# ATxmega128D3 device description
Architecture: AVR8_XMEGA; Family: AVR XMEGA
Registers are 8-bit, access not given, no defined reset value unless marked. A register's access mark holds for its fields unless they carry their own. Offsets are from the block's base; [hi:lo] are bit positions; {n}, {i} and the like mark numbered series; 'fields as' and 'values as' point back to an identical list.

## HIRES (TC module) — High-Resolution Extension
Instances: HIRESC 0x890
0x00 CTRLA — Control Register
  [1:0] HREN — High Resolution Enable
    0=NONE (No Fault Protection); 1=TC0 (Enable High Resolution on Timer/Counter 0); 2=TC1 (Enable High Resolution on Timer/Counter 1); 3=BOTH (Enable High Resolution both Timer/Counters)

## TC2 — 16-bit Timer/Counter type 2
Instances: TCC2 0x800, TCD2 0x900, TCE2 0xA00, TCF2 0xB00
0x00 CTRLA — Control Register A
  [3:0] CLKSEL — Clock Selection
    0=OFF (Timer Off); 1=DIV1 (System Clock); 2=DIV2 (System Clock / 2); 3=DIV4 (System Clock / 4); 4=DIV8 (System Clock / 8); 5=DIV64 (System Clock / 64); 6=DIV256 (System Clock / 256); 7=DIV1024 (System Clock / 1024); {v}=EVCH{v-8} (Event Channel {v-8}) (v=8..11)
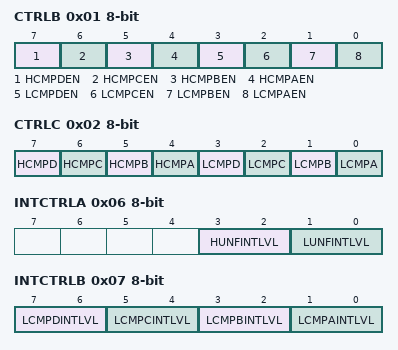
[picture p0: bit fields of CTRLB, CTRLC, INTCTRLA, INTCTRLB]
0x01 CTRLB — Control Register B
  [7] HCMPDEN — High Byte Compare D Enable
  [6] HCMPCEN — High Byte Compare C Enable
  [5] HCMPBEN — High Byte Compare B Enable
  [4] HCMPAEN — High Byte Compare A Enable
  [3] LCMPDEN — Low Byte Compare D Enable
  [2] LCMPCEN — Low Byte Compare C Enable
  [1] LCMPBEN — Low Byte Compare B Enable
  [0] LCMPAEN — Low Byte Compare A Enable
0x02 CTRLC — Control register C
  [7] HCMPD — High Byte Compare D Output Value
  [6] HCMPC — High Byte Compare C Output Value
  [5] HCMPB — High Byte Compare B Output Value
  [4] HCMPA — High Byte Compare A Output Value
  [3] LCMPD — Low Byte Compare D Output Value
  [2] LCMPC — Low Byte Compare C Output Value
  [1] LCMPB — Low Byte Compare B Output Value
  [0] LCMPA — Low Byte Compare A Output Value
0x04 CTRLE — Control Register E
  [1:0] BYTEM — Byte Mode
    0=NORMAL (16-bit mode); 1=BYTEMODE (Timer/Counter operating in byte mode only (TC2)); 2=SPLITMODE (Timer/Counter split into two 8-bit Counters)
0x06 INTCTRLA — Interrupt Control Register A
  [3:2] HUNFINTLVL — High Byte Underflow Interrupt Level
    0=OFF (Interrupt Disabled); 1=LO (Low Level); 2=MED (Medium Level); 3=HI (High Level)
  [1:0] LUNFINTLVL — Low Byte Underflow interrupt level
    values as HUNFINTLVL
0x07 INTCTRLB — Interrupt Control Register B
  [all] fields
    values as INTCTRLA.HUNFINTLVL
  [7:6] LCMPDINTLVL — Low Byte Compare D Interrupt Level
  [5:4] LCMPCINTLVL — Low Byte Compare C Interrupt Level
  [3:2] LCMPBINTLVL — Low Byte Compare B Interrupt Level
  [1:0] LCMPAINTLVL — Low Byte Compare A Interrupt Level
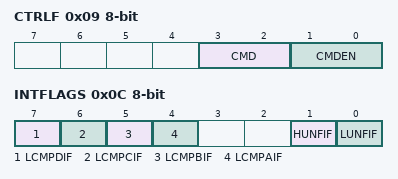
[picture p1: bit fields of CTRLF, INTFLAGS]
0x09 CTRLF — Control Register F
  [3:2] CMD — Command
    0=NONE (No Command); 2=RESTART (Force Restart); 3=RESET (Force Hard Reset)
  [1:0] CMDEN — Command Enable
    1=LOW (Low Byte Timer/Counter); 2=HIGH (High Byte Timer/Counter); 3=BOTH (Both Low Byte and High Byte Timer/Counters)
0x0C INTFLAGS — Interrupt Flag Register
  [7] LCMPDIF — Low Byte Compare D Interrupt Flag
  [6] LCMPCIF — Low Byte Compare C Interrupt Flag
  [5] LCMPBIF — Low Byte Compare B Interrupt Flag
  [4] LCMPAIF — Low Byte Compare A Interrupt Flag
  [1] HUNFIF — High Byte Underflow Interrupt Flag
  [0] LUNFIF — Low Byte Underflow Interrupt Flag
0x20 LCNT — Low Byte Count
0x21 HCNT — High Byte Count
0x26 LPER — Low Byte Period
0x27 HPER — High Byte Period
0x28 LCMPA — Low Byte Compare A
0x29 HCMPA — High Byte Compare A
0x2A LCMPB — Low Byte Compare B
0x2B HCMPB — High Byte Compare B
0x2C LCMPC — Low Byte Compare C
0x2D HCMPC — High Byte Compare C
0x2E LCMPD — Low Byte Compare D
0x2F HCMPD — High Byte Compare D

## USART — Universal Synchronous/Asynchronous Receiver/Transmitter
Instances: USARTC0 0x8A0, USARTD0 0x9A0, USARTE0 0xAA0
0x00 DATA
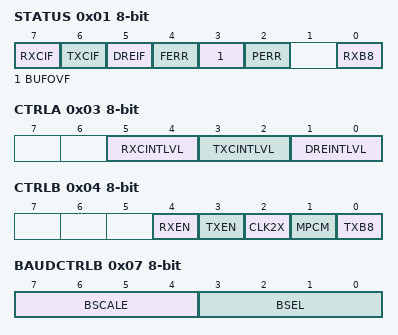
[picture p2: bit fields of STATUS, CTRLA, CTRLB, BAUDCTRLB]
0x01 STATUS
  [7] RXCIF — Receive Interrupt Flag
  [6] TXCIF — Transmit Interrupt Flag
  [5] DREIF — Data Register Empty Flag
  [4] FERR — Frame Error
  [3] BUFOVF — Buffer Overflow
  [2] PERR — Parity Error
  [0] RXB8 — Receive Bit 8
0x03 CTRLA — Control Register A
  [all] fields
    0=OFF (Interrupt Disabled); 1=LO (Low Level); 2=MED (Medium Level); 3=HI (High Level)
  [5:4] RXCINTLVL — Receive Interrupt Level
  [3:2] TXCINTLVL — Transmit Interrupt Level
  [1:0] DREINTLVL — Data Register Empty Interrupt Level
0x04 CTRLB — Control Register B
  [4] RXEN — Receiver Enable
  [3] TXEN — Transmitter Enable
  [2] CLK2X — Double transmission speed
  [1] MPCM — Multi-processor Communication Mode
  [0] TXB8 — Transmit bit 8
0x05 CTRLC — Control Register C
  [7:6] CMODE — Communication Mode
    0=ASYNCHRONOUS (Asynchronous Mode); 1=SYNCHRONOUS (Synchronous Mode); 2=IRDA (IrDA Mode); 3=MSPI (Master SPI Mode)
  [5:4] PMODE — Parity Mode
    0=DISABLED (No Parity); 2=EVEN (Even Parity); 3=ODD (Odd Parity)
  [3] SBMODE — Stop Bit Mode
  [2] UDORD — SPI Master Mode, Data Order
  [1] UCPHA — SPI Master Mode, Clock Phase
  [2:0] CHSIZE — Character Size
    {v}={v+5}BIT (Character size: {v+5} bit) (v=0..3); 7=9BIT (Character size: 9 bit)
0x06 BAUDCTRLA — Baud Rate Control Register A
  [7:0] BSEL — Baud Rate Selection Bits [7:0]
0x07 BAUDCTRLB — Baud Rate Control Register B
  [7:4] BSCALE — Baud Rate Scale
  [3:0] BSEL — Baud Rate Selection bits[11:8]

## SPI — Serial Peripheral Interface
Instances: SPIC 0x8C0, SPID 0x9C0, SPIE 0xAC0
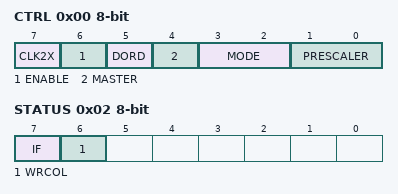
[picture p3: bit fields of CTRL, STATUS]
0x00 CTRL — Control Register
  [7] CLK2X — Enable Double Speed
  [6] ENABLE — Enable Module
  [5] DORD — Data Order Setting
  [4] MASTER — Master Operation Enable
  [3:2] MODE — SPI Mode
    {v}=SPI Mode {v} (v=0..3)
  [1:0] PRESCALER
    0=DIV4 (System Clock / 4); 1=DIV16 (System Clock / 16); 2=DIV64 (System Clock / 64); 3=DIV128 (System Clock / 128)
0x01 INTCTRL — Interrupt Control Register
  [1:0] INTLVL — Interrupt level
    0=OFF (Interrupt Disabled); 1=LO (Low Level); 2=MED (Medium Level); 3=HI (High Level)
0x02 STATUS
  [7] IF — Interrupt Flag
  [6] WRCOL — Write Collision
0x03 DATA

## IRCOM — IR Communication Module
Instances: IRCOM 0x8F8
0x00 CTRL — Control Register
  [3:0] EVSEL — Event Channel Select
    0=OFF (No Event Source); {v}=Event Channel {v-8} (v=8..15)
0x01 TXPLCTRL — IrDA Transmitter Pulse Length Control Register
0x02 RXPLCTRL — IrDA Receiver Pulse Length Control Register
